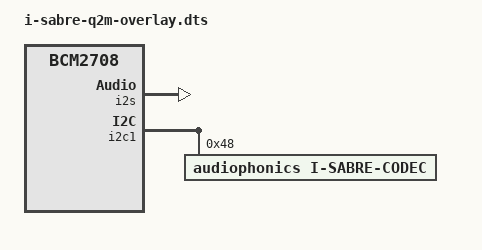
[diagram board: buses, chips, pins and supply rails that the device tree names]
// Definitions for I-Sabre Q2M
/dts-v1/;
/plugin/;

/ {
	compatible = "brcm,bcm2708";

	fragment@0 {
		target = <&sound>;
		frag0: __overlay__ {
			compatible = "audiophonics,i-sabre-q2m";
			i2s-controller = <&i2s>;
			status = "okay";
		};
	};

	fragment@1 {
		target = <&i2s>;
		__overlay__ {
			status = "okay";
		};
	};

	fragment@2 {
		target = <&i2c1>;
		__overlay__ {
			#address-cells = <1>;
			#size-cells = <0>;
			status = "okay";

			i-sabre-codec@48 {
				#sound-dai-cells = <0>;
				compatible = "audiophonics,i-sabre-codec";
				reg = <0x48>;
				status = "okay";
			};
		};
	};
};
